# APM32F446 register map
File version: 1.0
CPU: CM4 r0p1, little endian, MPU, FPU, 4 interrupt priority bits
Registers are 32-bit, read-write, reset 0x0 unless marked. A register's access mark holds for its fields unless they carry their own. Offsets are from the block's base; [hi:lo] are bit positions; {n}, {i} and the like mark numbered series; 'fields as' and 'values as' point back to an identical list.

## SCG — System Clock Generator
Base 0x40064000
0x00 VERID ro reset 0x1000000 — Version ID Register
  [31:0] VERID — Version Number
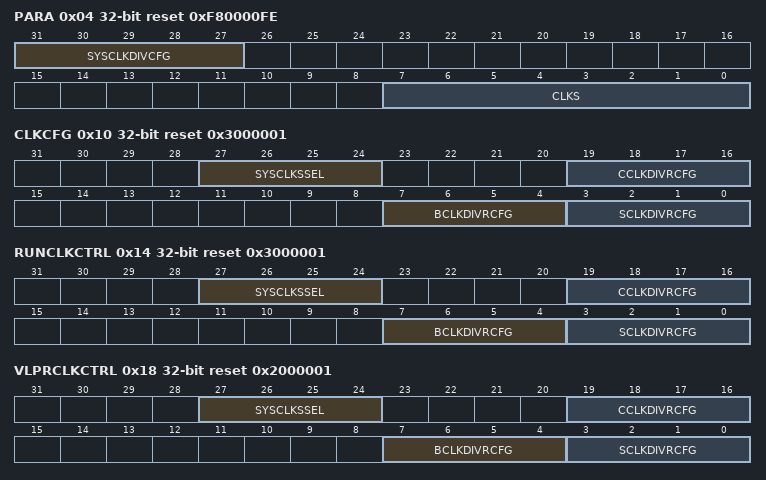
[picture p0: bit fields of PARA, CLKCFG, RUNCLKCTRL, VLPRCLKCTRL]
0x04 PARA ro reset 0xF80000FE — Parameter Register
  [31:27] SYSCLKDIVCFG — System Clock Divider Configure
  [7:0] CLKS — Clock Sources
0x10 CLKCFG ro reset 0x3000001 — Clock Configure Register
  [27:24] SYSCLKSSEL — System Clock Source Select
    1=System OSC (SYSOSC_CLK); 2=Low speed internal oscillator (LSI_CLK); 3=High speed internal oscillator (HSI_CLK); 6=System PLL (SYSPLL_CLK)
  [19:16] CCLKDIVRCFG — Core Clock Divide Ratio Configure
    {v}=Divide-by-{v+1} (v=0..15)
  [7:4] BCLKDIVRCFG — Bus Clock Divide Ratio Configure
    {v}=Divide-by-{v+1} (v=0..15)
  [3:0] SCLKDIVRCFG — Slow Clock Division Ratio Configure
    {v}=Divide-by-{v+1} (v=0..7)
0x14 RUNCLKCTRL reset 0x3000001 — Run Clock Control Register
  fields as CLKCFG
0x18 VLPRCLKCTRL reset 0x2000001 — VLPR Clock Control Register
  [27:24] SYSCLKSSEL — System Clock Source Select
    2=Low speed internal oscillator (LSI_CLK)
  [19:16] CCLKDIVRCFG — Core Clock Divide Ratio Configure
    {v}=Divide-by-{v+1} (v=0..15)
  [7:4] BCLKDIVRCFG — Bus Clock Divide Ratio Configure
    {v}=Divide-by-{v+1} (v=0..15)
  [3:0] SCLKDIVRCFG — Slow Clock Division Ratio Configure
    {v}=Divide-by-{v+1} (v=0..7)
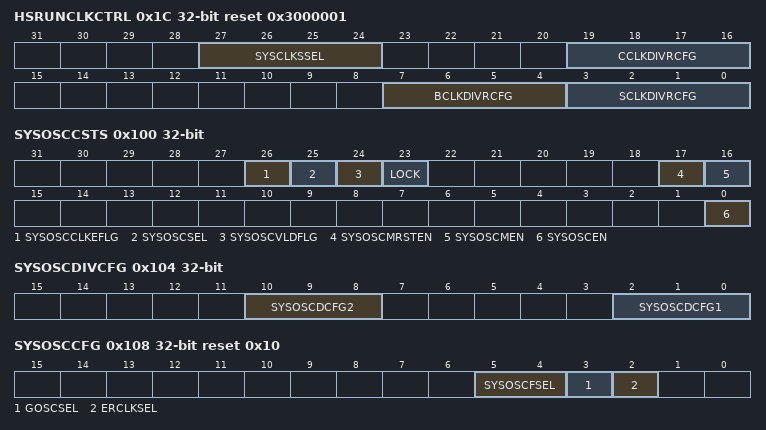
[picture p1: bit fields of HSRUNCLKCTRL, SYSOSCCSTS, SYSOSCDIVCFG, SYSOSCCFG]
0x1C HSRUNCLKCTRL reset 0x3000001 — HSRUN Clock Control Register
  [27:24] SYSCLKSSEL — System Clock Source Select
    3=High speed internal oscillator (HSI_CLK); 6=System PLL (SYSPLL_CLK)
  [19:16] CCLKDIVRCFG — Core Clock Divide Ratio Configure
    {v}=Divide-by-{v+1} (v=0..15)
  [7:4] BCLKDIVRCFG — Bus Clock Divide Ratio Configure
    {v}=Divide-by-{v+1} (v=0..15)
  [3:0] SCLKDIVRCFG — Slow Clock Division Ratio Configure
    {v}=Divide-by-{v+1} (v=0..7)
0x20 SYSCLKOSEL reset 0x3000000 — System Clock Output Select Register
  [27:24] SYSCLKOSEL — System Clock Output Select
    0=SCG SLOW Clock; 1=System OSC (SYSOSC_CLK); 2=Low speed internal oscillator (LSI_CLK); 3=High speed internal oscillator (HSI_CLK); 6=System PLL (SYSPLL_CLK)
0x100 SYSOSCCSTS — System OSC Control Status Register
  [26] SYSOSCCLKEFLG — System OSC Clock Error Flag
    0=System OSC Clock Monitor is disabled or has not detected an error; 1=System OSC Clock Monitor is enabled and detected an error
  [25] SYSOSCSEL ro — System OSC Select
    0=System OSC is not the system clock source; 1=System OSC is the system clock source
  [24] SYSOSCVLDFLG ro — System OSC Valid Flag
    0=System OSC is not enabled or clock is not valid; 1=System OSC is enabled and output clock is valid
  [23] LOCK
    0=This Control Status Register can be written; 1=This Control Status Register cannot be written
  [17] SYSOSCMRSTEN — System OSC Clock Monitor Reset Enable
    0=Clock Monitor generates interrupt when error detected; 1=Clock Monitor generates reset when error detected
  [16] SYSOSCMEN — System OSC Clock Monitor Enable
    0=System OSC Clock Monitor is disabled; 1=System OSC Clock Monitor is enabled
  [0] SYSOSCEN — System OSC Enable
    0=System OSC is disabled; 1=System OSC is enabled
0x104 SYSOSCDIVCFG — System OSC Divide Configure Register
  [10:8] SYSOSCDCFG2 — System OSC Clock Divide 2 Configure
    0=Output disabled; 1=Divide by 1; 2=Divide by 2; 3=Divide by 4; 4=Divide by 8; 5=Divide by 16; 6=Divide by 32; 7=Divide by 64
  [2:0] SYSOSCDCFG1 — System Clock Divide 1 Configure
    values as SYSOSCDCFG2
0x108 SYSOSCCFG reset 0x10 — System Oscillator Configure Register
  [5:4] SYSOSCFSEL — System OSC Frequency Select
    1=Low frequency range selected for the crystal oscillator; 2=Medium frequency range selected for the crytstal oscillator; 3=High frequency range selected for the crystal oscillator
  [3] GOSCSEL — Gain Oscillator Select
    0=Configure crystal oscillator for low-gain operation; 1=Configure crystal oscillator for high-gain operation
  [2] ERCLKSEL — External Reference Clock Select
    0=External reference clock selected; 1=Internal crystal oscillator of OSC selected
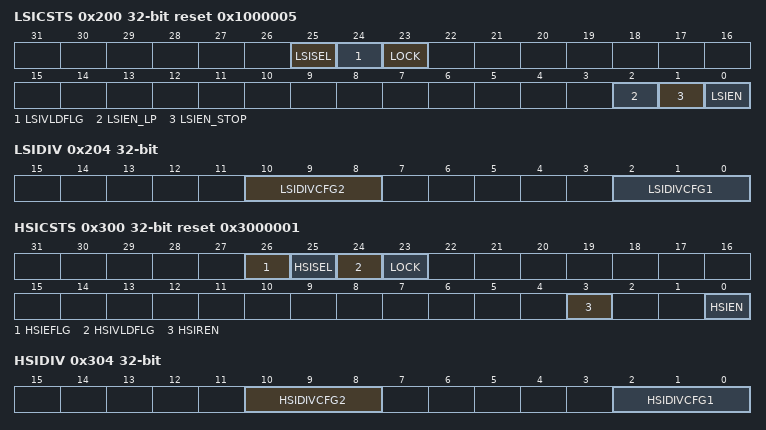
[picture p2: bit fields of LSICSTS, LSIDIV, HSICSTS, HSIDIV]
0x200 LSICSTS reset 0x1000005 — LSI Control Status Register
  [25] LSISEL ro — LSI Select
    0=Low Speed Internal oscillator is not the system clock source; 1=Low Speed Internal oscillator is the system clock source
  [24] LSIVLDFLG ro — LSI Valid Flag
    0=Low Speed Internal oscillator is not enabled or clock is not valid; 1=Low Speed Internal oscillator is enabled and output clock is valid
  [23] LOCK
    0=Control Status Register can be written; 1=Control Status Register cannot be written
  [2] LSIEN_LP — LSI Low Power Enable
    0=Low Speed Internal oscillator is disabled in VLP modes; 1=Low Speed Internal oscillator is enabled in VLP modes
  [1] LSIEN_STOP — LSI in STOP Mode Enable
    0=Low Speed Internal oscillator is disabled in supported Stop modes; 1=Low Speed Internal oscillator is enabled in supported Stop modes
  [0] LSIEN — LSI Enable
    0=Low Speed Internal oscillator is disabled; 1=Low Speed Internal oscillator is enabled
0x204 LSIDIV — LSI Divide Register
  [10:8] LSIDIVCFG2 — LSI Divide 2 Configure
    values as SYSOSCDIVCFG.SYSOSCDCFG2
  [2:0] LSIDIVCFG1 — LSI Divide 1 Configure
    values as SYSOSCDIVCFG.SYSOSCDCFG2
0x208 LSIFSEL reset 0x1 — LSI Frequency Select Register
  [0] LSIFSEL — LSICLK Frequency Select
    0=Low Speed Internal oscillator low range clock (2 MHz); 1=Low Speed Internal oscillator high range clock (8 MHz )
0x300 HSICSTS reset 0x3000001 — HSI Control Status Register
  [26] HSIEFLG — HSI Error Flag
    0=Error not detected with the High speed internal oscillator trimming; 1=Error detected with the High speed internal oscillator trimming
  [25] HSISEL ro — HSI Select
    0=High speed internal oscillator is not the system clock source; 1=High speed internal oscillator is the system clock source
  [24] HSIVLDFLG ro — HSI Valid Flag
    0=High speed internal oscillator is not enabled or clock is not valid; 1=High speed internal oscillator is enabled and output clock is valid. The clock is valid once there is an output clock from the HSICLK analog.
  [23] LOCK
    values as LSICSTS.LOCK
  [3] HSIREN — HSI Regulator Enable
    0=High speed internal oscillator Regulator is enabled; 1=High speed internal oscillator Regulator is disabled
  [0] HSIEN — HSI Enable
    0=High speed internal oscillator is disabled; 1=High speed internal oscillator is enabled
0x304 HSIDIV — HSI Divide Register
  [10:8] HSIDIVCFG2 — HSI Divide 2 Configure
    values as SYSOSCDIVCFG.SYSOSCDCFG2
  [2:0] HSIDIVCFG1 — HSI Divide 1 Configure
    values as SYSOSCDIVCFG.SYSOSCDCFG2
0x308 HSIFSEL — HSI Frequency Select Register
  [1:0] HSIFSEL — HSI Frequency Select
    0=High speed internal oscillator is trimmed to 48 MHz
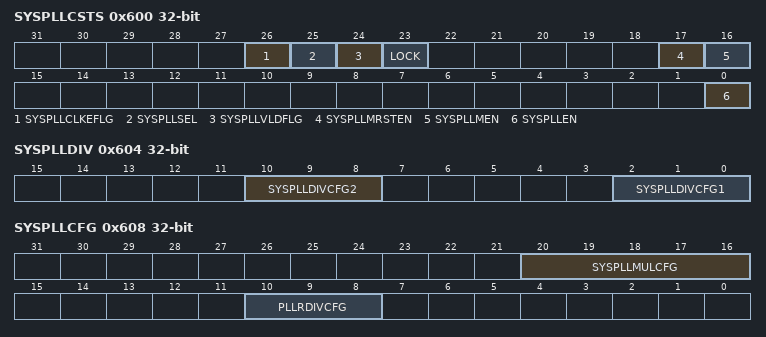
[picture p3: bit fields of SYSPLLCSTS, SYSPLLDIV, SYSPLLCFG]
0x600 SYSPLLCSTS — System PLL Control Status Register
  [26] SYSPLLCLKEFLG — System PLL Clock Error Flag
    0=System PLL Clock Monitor is disabled or has not detected an error; 1=System PLL Clock Monitor is enabled and detected an error. System PLL Clock Error flag will not set when System OSC is selected as its source and SYSOSCERR has set.
  [25] SYSPLLSEL ro — System PLL Select
    0=System PLL is not the system clock source; 1=System PLL is the system clock source
  [24] SYSPLLVLDFLG ro — System PLL Valid Flag
    0=System PLL is not enabled or clock is not valid; 1=System PLL is enabled and output clock is valid
  [23] LOCK
    values as LSICSTS.LOCK
  [17] SYSPLLMRSTEN — System PLL Clock Monitor Reset Enable
    values as SYSOSCCSTS.SYSOSCMRSTEN
  [16] SYSPLLMEN — System PLL Clock Monitor Enable
    0=System PLL Clock Monitor is disabled; 1=System PLL Clock Monitor is enabled
  [0] SYSPLLEN — System PLL Enable
    0=System PLL is disabled; 1=System PLL is enabled
0x604 SYSPLLDIV — System PLL Divide Register
  [10:8] SYSPLLDIVCFG2 — System PLL Clock Divide 2 Configuration
    0=Clock disabled; 1=Divide by 1; 2=Divide by 2; 3=Divide by 4; 4=Divide by 8; 5=Divide by 16; 6=Divide by 32; 7=Divide by 64
  [2:0] SYSPLLDIVCFG1 — System PLL Clock Divide 1 Configuration
    values as SYSPLLDIVCFG2
0x608 SYSPLLCFG — System PLL Configuration Register
  [20:16] SYSPLLMULCFG — System PLL Multiply Factor Configuration
  [10:8] PLLRDIVCFG — PLL Reference Clock Divider Configure
    {v}=Divide Factor is {v+1} (v=0..7)
